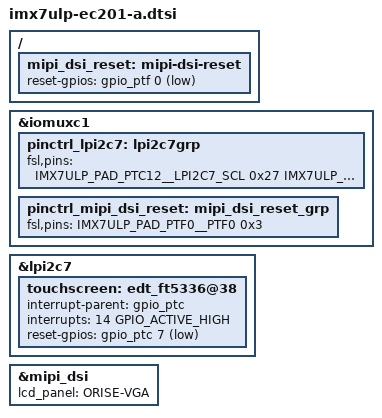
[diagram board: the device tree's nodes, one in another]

/*
 * Copyright 2019 FLIR
 *
 * This program is free software; you can redistribute it and/or modify
 * it under the terms of the GNU General Public License version 2 as
 * published by the Free Software Foundation.
 */

 
/* This device tree is for board ec201 revision a  */


/ {
	mipi_dsi_reset: mipi-dsi-reset {
		reset-gpios = <&gpio_ptf 0 GPIO_ACTIVE_LOW>;   // Dummy GPIO, not used

	};
};




&iomuxc1 {

	pinctrl_lpi2c7: lpi2c7grp {
		fsl,pins = <
			IMX7ULP_PAD_PTC12__LPI2C7_SCL   0x27
			IMX7ULP_PAD_PTC13__LPI2C7_SDA   0x27
			IMX7ULP_PAD_PTC14__PTC14        0x3 /* PCAPINT_n */
			IMX7ULP_PAD_PTC7__PTC7          0x3 /* TP_RESET_n */
			>;
	};

	pinctrl_mipi_dsi_reset: mipi_dsi_reset_grp {
		fsl,pins = <
			IMX7ULP_PAD_PTF0__PTF0    0x3 /* Dummy */
			>;
	};

};


/* Touch screen */
&lpi2c7 {

	touchscreen:edt_ft5336@38 {
		interrupt-parent = <&gpio_ptc>;
		interrupts = <14 GPIO_ACTIVE_HIGH>;
		reset-gpios = <&gpio_ptc 7 GPIO_ACTIVE_LOW>;
	};
};


/* LCD */
&mipi_dsi {
	lcd_panel = "ORISE-VGA";
};
